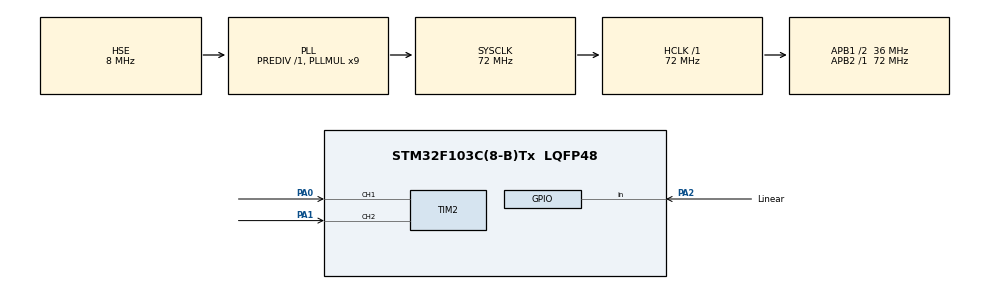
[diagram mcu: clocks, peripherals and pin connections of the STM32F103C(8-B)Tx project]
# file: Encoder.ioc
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Mcu.Family=STM32F1
Mcu.Name=STM32F103C(8-B)Tx
Mcu.Package=LQFP48
NVIC.PriorityGroup=NVIC_PRIORITYGROUP_4
NVIC.TIM2_IRQn=true\:0\:0\:false\:false\:true\:true\:true\:true
PA0-WKUP.Signal=S_TIM2_CH1_ETR
PA1.Signal=S_TIM2_CH2
PA13.Mode=Serial_Wire
PA13.Signal=SYS_JTMS-SWDIO
PA14.Mode=Serial_Wire
PA14.Signal=SYS_JTCK-SWCLK
PA2.GPIO_Label=Linear
PA2.GPIO_PuPd=GPIO_PULLUP
PA2.Signal=GPIO_Input
PD0-OSC_IN.Mode=HSE-External-Oscillator
PD0-OSC_IN.Signal=RCC_OSC_IN
PD1-OSC_OUT.Mode=HSE-External-Oscillator
PD1-OSC_OUT.Signal=RCC_OSC_OUT
ProjectManager.HeapSize=0x200
ProjectManager.StackSize=0x400
ProjectManager.TargetToolchain=STM32CubeIDE
RCC.AHBFreq_Value=72000000
RCC.APB1CLKDivider=RCC_HCLK_DIV2
RCC.APB1Freq_Value=36000000
RCC.APB1TimFreq_Value=72000000
RCC.APB2Freq_Value=72000000
RCC.APB2TimFreq_Value=72000000
RCC.HCLKFreq_Value=72000000
RCC.PLLMUL=RCC_PLL_MUL9
RCC.PLLSourceVirtual=RCC_PLLSOURCE_HSE
RCC.SYSCLKFreq_VALUE=72000000
RCC.SYSCLKSource=RCC_SYSCLKSOURCE_PLLCLK
RCC.USBFreq_Value=72000000
SH.S_TIM2_CH1_ETR.0=TIM2_CH1,Encoder_Interface
SH.S_TIM2_CH2.0=TIM2_CH2,Encoder_Interface
TIM2.EncoderMode=TIM_ENCODERMODE_TI12
TIM2.IC1Polarity=TIM_ICPOLARITY_FALLING
TIM2.IC2Polarity=TIM_ICPOLARITY_FALLING
TIM3.Prescaler=71
VP_TIM3_VS_ClockSourceINT.Mode=Internal
board=custom

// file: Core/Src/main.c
/* USER CODE BEGIN Header */
/**
  ******************************************************************************
  * @file           : main.c
  * @brief          : Main program body
  ******************************************************************************
  * @attention
  *
  * Copyright (c) 2023 STMicroelectronics.
  * All rights reserved.
  *
  * This software is licensed under terms that can be found in the LICENSE file
  * in the root directory of this software component.
  * If no LICENSE file comes with this software, it is provided AS-IS.
  *
  ******************************************************************************
  */
/* USER CODE END Header */
#include "main.h"

/* USER CODE BEGIN Includes */
#include "stdbool.h"
/* USER CODE END Includes */

TIM_HandleTypeDef htim2;
TIM_HandleTypeDef htim3;

void SystemClock_Config(void);
static void MX_GPIO_Init(void);
static void MX_TIM2_Init(void);
static void MX_TIM3_Init(void);

/* USER CODE BEGIN 0 */
volatile bool state = false;
volatile int16_t counter = 0;
volatile int16_t count = 0;
volatile uint32_t last_time;
volatile bool startstate = true;

volatile uint32_t enc_time = 0;

void Delay_us(uint16_t t)
{
		__HAL_TIM_SET_COUNTER(&htim3,0);  // set the counter value a 0
		while (__HAL_TIM_GET_COUNTER(&htim3) < t);  // wait for the counter to reach the us input in the paramete
}
void Delay_ms(uint32_t t)
{
	for(uint32_t i =0;i<1000;i++)
		Delay_us(t);
}
void HAL_TIM_IC_CaptureCallback(TIM_HandleTypeDef *htim)
{
		if(startstate == true)
		{
			__disable_irq();
			startstate = false;
			Delay_ms(20);
			__enable_irq();
		}
		else
		{
//			if(HAL_GetTick() - enc_time > )
			counter = (int16_t)__HAL_TIM_GET_COUNTER(htim);
			count = counter/4;
		}

}

/* USER CODE END 0 */

int main(void)
{

  /* MCU Configuration--------------------------------------------------------*/

  /* Reset of all peripherals, Initializes the Flash interface and the Systick. */
  HAL_Init();

  /* Configure the system clock */
  SystemClock_Config();

  /* Initialize all configured peripherals */
  MX_GPIO_Init();
  MX_TIM2_Init();
  MX_TIM3_Init();
  /* USER CODE BEGIN 2 */
  last_time = HAL_GetTick();
  HAL_TIM_Base_Start(&htim3);
  HAL_TIM_Encoder_Start_IT(&htim2, TIM_CHANNEL_ALL);

	__disable_irq();
	Delay_ms(2000);
	__enable_irq();
  /* USER CODE END 2 */

  /* Infinite loop */
  while (1)
  {

    /* USER CODE BEGIN 3 */
	  //state = HAL_GPIO_ReadPin(Linear_GPIO_Port, Linear_Pin);
	  //HAL_Delay(100);
	  if(HAL_GetTick()-last_time>1000 && startstate == false)
	  {
		  startstate = true;
		  last_time = HAL_GetTick();
	  }

  }
  /* USER CODE END 3 */
}

void SystemClock_Config(void)
{
  RCC_OscInitTypeDef RCC_OscInitStruct = {0};
  RCC_ClkInitTypeDef RCC_ClkInitStruct = {0};

  /** Initializes the RCC Oscillators according to the specified parameters
  * in the RCC_OscInitTypeDef structure.
  */
  RCC_OscInitStruct.OscillatorType = RCC_OSCILLATORTYPE_HSE;
  RCC_OscInitStruct.HSEState = RCC_HSE_ON;
  RCC_OscInitStruct.HSEPredivValue = RCC_HSE_PREDIV_DIV1;
  RCC_OscInitStruct.HSIState = RCC_HSI_ON;
  RCC_OscInitStruct.PLL.PLLState = RCC_PLL_ON;
  RCC_OscInitStruct.PLL.PLLSource = RCC_PLLSOURCE_HSE;
  RCC_OscInitStruct.PLL.PLLMUL = RCC_PLL_MUL9;
  if (HAL_RCC_OscConfig(&RCC_OscInitStruct) != HAL_OK)
  {
    Error_Handler();
  }

  /** Initializes the CPU, AHB and APB buses clocks
  */
  RCC_ClkInitStruct.ClockType = RCC_CLOCKTYPE_HCLK|RCC_CLOCKTYPE_SYSCLK
                              |RCC_CLOCKTYPE_PCLK1|RCC_CLOCKTYPE_PCLK2;
  RCC_ClkInitStruct.SYSCLKSource = RCC_SYSCLKSOURCE_PLLCLK;
  RCC_ClkInitStruct.AHBCLKDivider = RCC_SYSCLK_DIV1;
  RCC_ClkInitStruct.APB1CLKDivider = RCC_HCLK_DIV2;
  RCC_ClkInitStruct.APB2CLKDivider = RCC_HCLK_DIV1;

  if (HAL_RCC_ClockConfig(&RCC_ClkInitStruct, FLASH_LATENCY_2) != HAL_OK)
  {
    Error_Handler();
  }
}

static void MX_TIM2_Init(void)
{

  TIM_Encoder_InitTypeDef sConfig = {0};
  TIM_MasterConfigTypeDef sMasterConfig = {0};

  htim2.Instance = TIM2;
  htim2.Init.Prescaler = 0;
  htim2.Init.CounterMode = TIM_COUNTERMODE_UP;
  htim2.Init.Period = 65535;
  htim2.Init.ClockDivision = TIM_CLOCKDIVISION_DIV1;
  htim2.Init.AutoReloadPreload = TIM_AUTORELOAD_PRELOAD_DISABLE;
  sConfig.EncoderMode = TIM_ENCODERMODE_TI12;
  sConfig.IC1Polarity = TIM_ICPOLARITY_FALLING;
  sConfig.IC1Selection = TIM_ICSELECTION_DIRECTTI;
  sConfig.IC1Prescaler = TIM_ICPSC_DIV1;
  sConfig.IC1Filter = 0;
  sConfig.IC2Polarity = TIM_ICPOLARITY_FALLING;
  sConfig.IC2Selection = TIM_ICSELECTION_DIRECTTI;
  sConfig.IC2Prescaler = TIM_ICPSC_DIV1;
  sConfig.IC2Filter = 0;
  if (HAL_TIM_Encoder_Init(&htim2, &sConfig) != HAL_OK)
  {
    Error_Handler();
  }
  sMasterConfig.MasterOutputTrigger = TIM_TRGO_RESET;
  sMasterConfig.MasterSlaveMode = TIM_MASTERSLAVEMODE_DISABLE;
  if (HAL_TIMEx_MasterConfigSynchronization(&htim2, &sMasterConfig) != HAL_OK)
  {
    Error_Handler();
  }

}

static void MX_TIM3_Init(void)
{

  TIM_ClockConfigTypeDef sClockSourceConfig = {0};
  TIM_MasterConfigTypeDef sMasterConfig = {0};

  htim3.Instance = TIM3;
  htim3.Init.Prescaler = 71;
  htim3.Init.CounterMode = TIM_COUNTERMODE_UP;
  htim3.Init.Period = 65535;
  htim3.Init.ClockDivision = TIM_CLOCKDIVISION_DIV1;
  htim3.Init.AutoReloadPreload = TIM_AUTORELOAD_PRELOAD_DISABLE;
  if (HAL_TIM_Base_Init(&htim3) != HAL_OK)
  {
    Error_Handler();
  }
  sClockSourceConfig.ClockSource = TIM_CLOCKSOURCE_INTERNAL;
  if (HAL_TIM_ConfigClockSource(&htim3, &sClockSourceConfig) != HAL_OK)
  {
    Error_Handler();
  }
  sMasterConfig.MasterOutputTrigger = TIM_TRGO_RESET;
  sMasterConfig.MasterSlaveMode = TIM_MASTERSLAVEMODE_DISABLE;
  if (HAL_TIMEx_MasterConfigSynchronization(&htim3, &sMasterConfig) != HAL_OK)
  {
    Error_Handler();
  }

}

static void MX_GPIO_Init(void)
{
  GPIO_InitTypeDef GPIO_InitStruct = {0};

  /* GPIO Ports Clock Enable */
  __HAL_RCC_GPIOD_CLK_ENABLE();
  __HAL_RCC_GPIOA_CLK_ENABLE();

  /*Configure GPIO pin : Linear_Pin */
  GPIO_InitStruct.Pin = Linear_Pin;
  GPIO_InitStruct.Mode = GPIO_MODE_INPUT;
  GPIO_InitStruct.Pull = GPIO_PULLUP;
  HAL_GPIO_Init(Linear_GPIO_Port, &GPIO_InitStruct);

}

void Error_Handler(void)
{
  __disable_irq();
  while (1)
  {
  }
}
